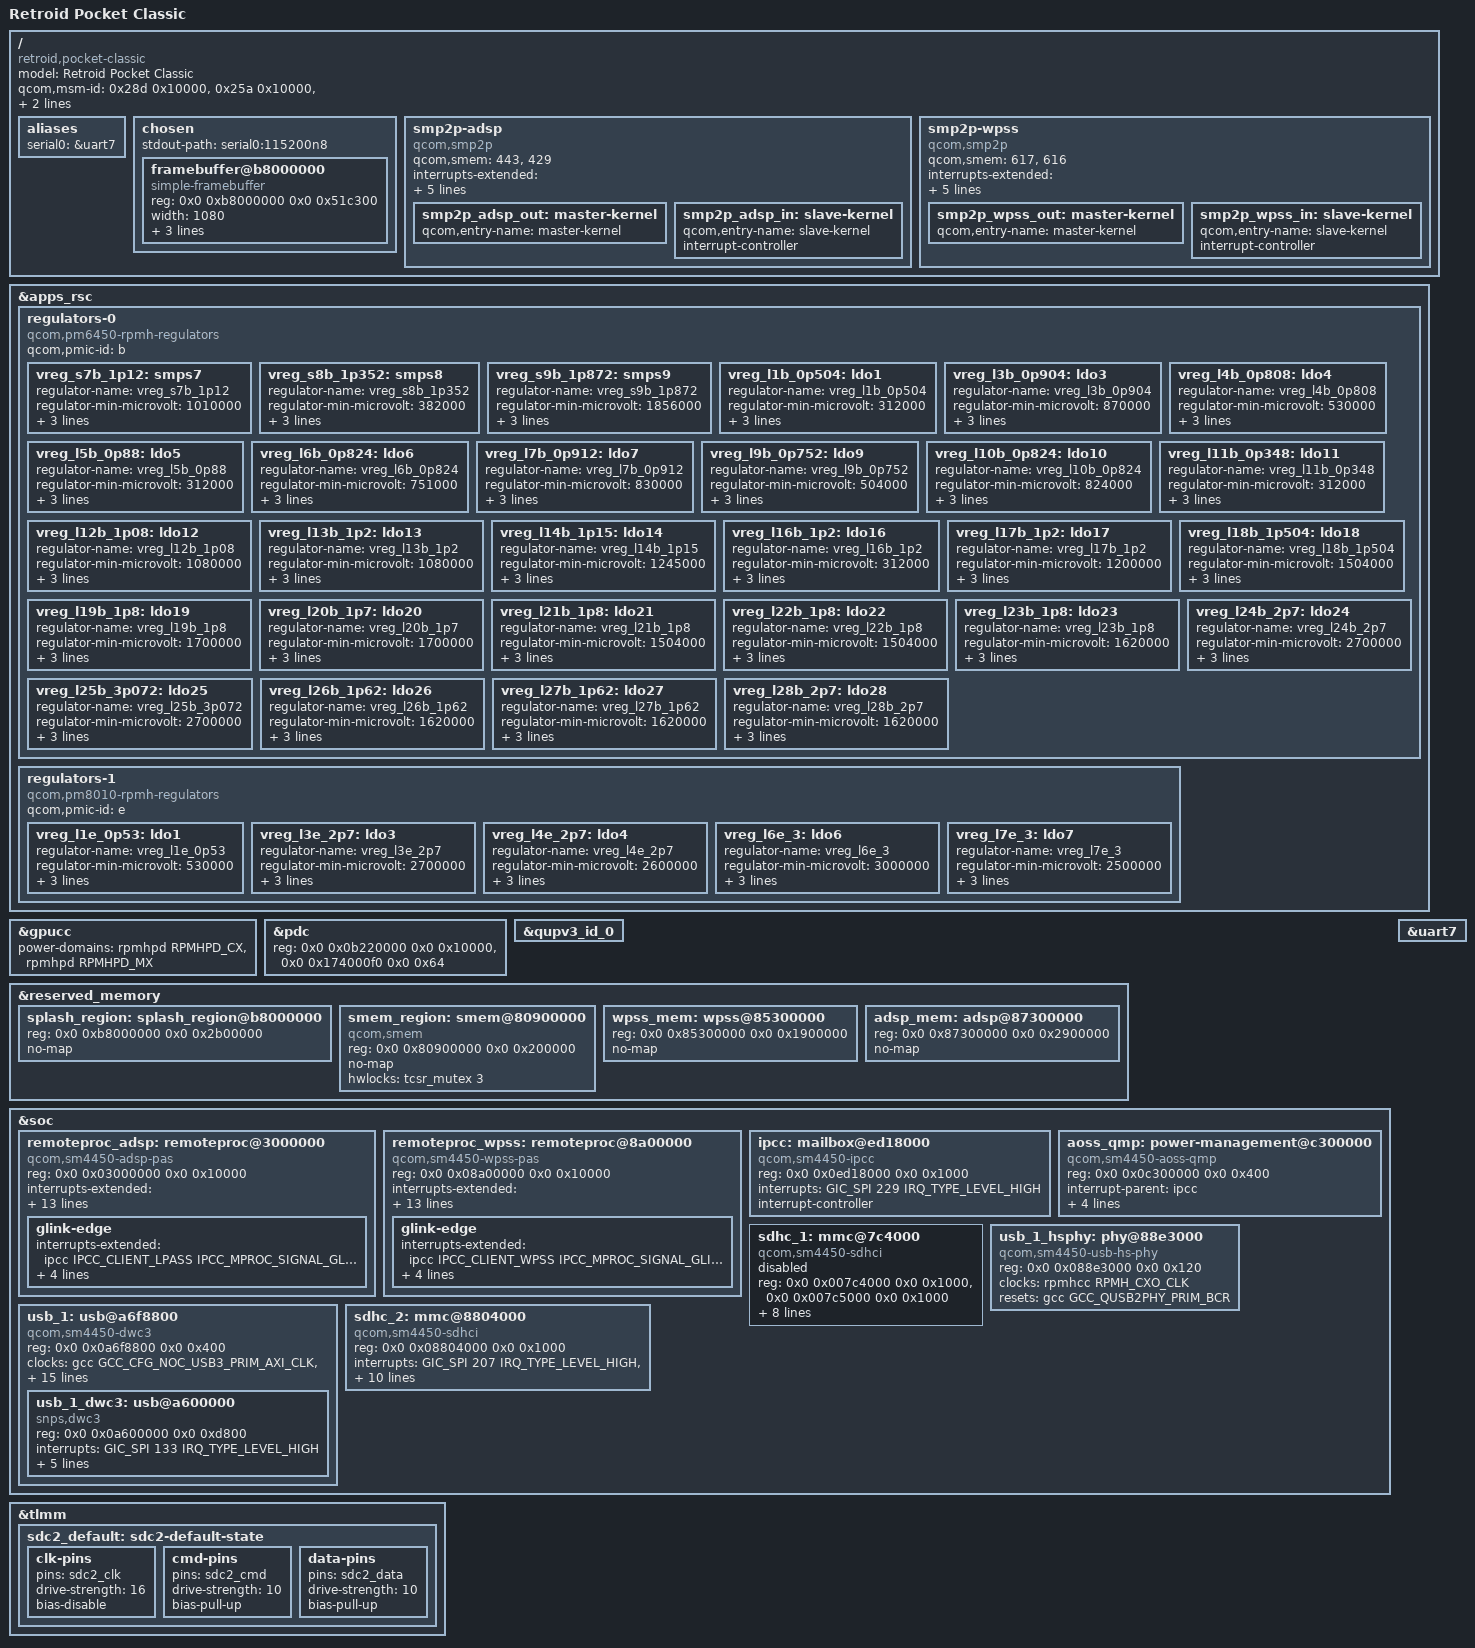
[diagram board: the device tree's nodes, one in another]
// SPDX-License-Identifier: BSD-3-Clause
/*
 * Retroid Pocket Classic (SM4450 "parrot")
 *
 * Hardware data from the live Android DT dump (2026-08-22).
 */

/dts-v1/;

#include <dt-bindings/gpio/gpio.h>
#include <dt-bindings/mailbox/qcom-ipcc.h>
#include <dt-bindings/regulator/qcom,rpmh-regulator.h>
#include "sm4450.dtsi"
/ {
	model = "Retroid Pocket Classic";
	compatible = "retroid,pocket-classic", "qcom,sm4450";
	qcom,msm-id = <0x28d 0x10000>, <0x25a 0x10000>, <0x28e 0x10000>;
	qcom,board-id = <0x1000b 0>;

	aliases {
		serial0 = &uart7;
	};

	chosen {
		#address-cells = <2>;
		#size-cells = <2>;
		ranges;
		stdout-path = "serial0:115200n8";

		framebuffer@b8000000 {
			compatible = "simple-framebuffer";
			reg = <0x0 0xb8000000 0x0 0x51c300>;
			width = <1080>;
			height = <1240>;
			stride = <4320>;
			format = "x8r8g8b8";
			status = "okay";
		};
	};

	smp2p-adsp {
		compatible = "qcom,smp2p";
		qcom,smem = <443>, <429>;
		interrupts-extended = <&ipcc IPCC_CLIENT_LPASS
					     IPCC_MPROC_SIGNAL_SMP2P
					     IRQ_TYPE_EDGE_RISING>;
		mboxes = <&ipcc IPCC_CLIENT_LPASS IPCC_MPROC_SIGNAL_SMP2P>;
		qcom,local-pid = <0>;
		qcom,remote-pid = <2>;

		smp2p_adsp_out: master-kernel {
			qcom,entry-name = "master-kernel";
			#qcom,smem-state-cells = <1>;
		};

		smp2p_adsp_in: slave-kernel {
			qcom,entry-name = "slave-kernel";
			interrupt-controller;
			#interrupt-cells = <2>;
		};
	};

	smp2p-wpss {
		compatible = "qcom,smp2p";
		qcom,smem = <617>, <616>;
		interrupts-extended = <&ipcc IPCC_CLIENT_WPSS
					     IPCC_MPROC_SIGNAL_SMP2P
					     IRQ_TYPE_EDGE_RISING>;
		mboxes = <&ipcc IPCC_CLIENT_WPSS IPCC_MPROC_SIGNAL_SMP2P>;
		qcom,local-pid = <0>;
		qcom,remote-pid = <13>;

		smp2p_wpss_out: master-kernel {
			qcom,entry-name = "master-kernel";
			#qcom,smem-state-cells = <1>;
		};

		smp2p_wpss_in: slave-kernel {
			qcom,entry-name = "slave-kernel";
			interrupt-controller;
			#interrupt-cells = <2>;
		};
	};
};

&apps_rsc {
	/* Voltage constraints extracted from the live parrot (RP Classic) DT */
	regulators-0 {
		compatible = "qcom,pm6450-rpmh-regulators";
		qcom,pmic-id = "b";

		vreg_s7b_1p12: smps7 {
			regulator-name = "vreg_s7b_1p12";
			regulator-min-microvolt = <1010000>;
			regulator-max-microvolt = <1170000>;
			regulator-initial-mode = <RPMH_REGULATOR_MODE_HPM>;
		};
		vreg_s8b_1p352: smps8 {
			regulator-name = "vreg_s8b_1p352";
			regulator-min-microvolt = <382000>;
			regulator-max-microvolt = <1744000>;
			regulator-initial-mode = <RPMH_REGULATOR_MODE_HPM>;
		};
		vreg_s9b_1p872: smps9 {
			regulator-name = "vreg_s9b_1p872";
			regulator-min-microvolt = <1856000>;
			regulator-max-microvolt = <2040000>;
			regulator-initial-mode = <RPMH_REGULATOR_MODE_HPM>;
		};
		vreg_l1b_0p504: ldo1 {
			regulator-name = "vreg_l1b_0p504";
			regulator-min-microvolt = <312000>;
			regulator-max-microvolt = <650000>;
			regulator-initial-mode = <RPMH_REGULATOR_MODE_HPM>;
		};
		vreg_l3b_0p904: ldo3 {
			regulator-name = "vreg_l3b_0p904";
			regulator-min-microvolt = <870000>;
			regulator-max-microvolt = <970000>;
			regulator-initial-mode = <RPMH_REGULATOR_MODE_HPM>;
		};
		vreg_l4b_0p808: ldo4 {
			regulator-name = "vreg_l4b_0p808";
			regulator-min-microvolt = <530000>;
			regulator-max-microvolt = <860000>;
			regulator-initial-mode = <RPMH_REGULATOR_MODE_HPM>;
		};
		vreg_l5b_0p88: ldo5 {
			regulator-name = "vreg_l5b_0p88";
			regulator-min-microvolt = <312000>;
			regulator-max-microvolt = <1052000>;
			regulator-initial-mode = <RPMH_REGULATOR_MODE_HPM>;
		};
		vreg_l6b_0p824: ldo6 {
			regulator-name = "vreg_l6b_0p824";
			regulator-min-microvolt = <751000>;
			regulator-max-microvolt = <824000>;
			regulator-initial-mode = <RPMH_REGULATOR_MODE_HPM>;
		};
		vreg_l7b_0p912: ldo7 {
			regulator-name = "vreg_l7b_0p912";
			regulator-min-microvolt = <830000>;
			regulator-max-microvolt = <920000>;
			regulator-initial-mode = <RPMH_REGULATOR_MODE_HPM>;
		};
		vreg_l9b_0p752: ldo9 {
			regulator-name = "vreg_l9b_0p752";
			regulator-min-microvolt = <504000>;
			regulator-max-microvolt = <824000>;
			regulator-initial-mode = <RPMH_REGULATOR_MODE_HPM>;
		};
		vreg_l10b_0p824: ldo10 {
			regulator-name = "vreg_l10b_0p824";
			regulator-min-microvolt = <824000>;
			regulator-max-microvolt = <901000>;
			regulator-initial-mode = <RPMH_REGULATOR_MODE_HPM>;
		};
		vreg_l11b_0p348: ldo11 {
			regulator-name = "vreg_l11b_0p348";
			regulator-min-microvolt = <312000>;
			regulator-max-microvolt = <752000>;
			regulator-initial-mode = <RPMH_REGULATOR_MODE_HPM>;
		};
		vreg_l12b_1p08: ldo12 {
			regulator-name = "vreg_l12b_1p08";
			regulator-min-microvolt = <1080000>;
			regulator-max-microvolt = <1304000>;
			regulator-initial-mode = <RPMH_REGULATOR_MODE_HPM>;
		};
		vreg_l13b_1p2: ldo13 {
			regulator-name = "vreg_l13b_1p2";
			regulator-min-microvolt = <1080000>;
			regulator-max-microvolt = <1304000>;
			regulator-initial-mode = <RPMH_REGULATOR_MODE_HPM>;
		};
		vreg_l14b_1p15: ldo14 {
			regulator-name = "vreg_l14b_1p15";
			regulator-min-microvolt = <1245000>;
			regulator-max-microvolt = <1304000>;
			regulator-initial-mode = <RPMH_REGULATOR_MODE_HPM>;
		};
		vreg_l16b_1p2: ldo16 {
			regulator-name = "vreg_l16b_1p2";
			regulator-min-microvolt = <312000>;
			regulator-max-microvolt = <1260000>;
			regulator-initial-mode = <RPMH_REGULATOR_MODE_HPM>;
		};
		vreg_l17b_1p2: ldo17 {
			regulator-name = "vreg_l17b_1p2";
			regulator-min-microvolt = <1200000>;
			regulator-max-microvolt = <1200000>;
			regulator-initial-mode = <RPMH_REGULATOR_MODE_HPM>;
		};
		vreg_l18b_1p504: ldo18 {
			regulator-name = "vreg_l18b_1p504";
			regulator-min-microvolt = <1504000>;
			regulator-max-microvolt = <2000000>;
			regulator-initial-mode = <RPMH_REGULATOR_MODE_HPM>;
		};
		vreg_l19b_1p8: ldo19 {
			regulator-name = "vreg_l19b_1p8";
			regulator-min-microvolt = <1700000>;
			regulator-max-microvolt = <1950000>;
			regulator-initial-mode = <RPMH_REGULATOR_MODE_HPM>;
		};
		vreg_l20b_1p7: ldo20 {
			regulator-name = "vreg_l20b_1p7";
			regulator-min-microvolt = <1700000>;
			regulator-max-microvolt = <1900000>;
			regulator-initial-mode = <RPMH_REGULATOR_MODE_HPM>;
		};
		vreg_l21b_1p8: ldo21 {
			regulator-name = "vreg_l21b_1p8";
			regulator-min-microvolt = <1504000>;
			regulator-max-microvolt = <2000000>;
			regulator-initial-mode = <RPMH_REGULATOR_MODE_HPM>;
		};
		vreg_l22b_1p8: ldo22 {
			regulator-name = "vreg_l22b_1p8";
			regulator-min-microvolt = <1504000>;
			regulator-max-microvolt = <2000000>;
			regulator-initial-mode = <RPMH_REGULATOR_MODE_HPM>;
		};
		vreg_l23b_1p8: ldo23 {
			regulator-name = "vreg_l23b_1p8";
			regulator-min-microvolt = <1620000>;
			regulator-max-microvolt = <1980000>;
			regulator-initial-mode = <RPMH_REGULATOR_MODE_HPM>;
		};
		vreg_l24b_2p7: ldo24 {
			regulator-name = "vreg_l24b_2p7";
			regulator-min-microvolt = <2700000>;
			regulator-max-microvolt = <3544000>;
			regulator-initial-mode = <RPMH_REGULATOR_MODE_HPM>;
		};
		vreg_l25b_3p072: ldo25 {
			regulator-name = "vreg_l25b_3p072";
			regulator-min-microvolt = <2700000>;
			regulator-max-microvolt = <3544000>;
			regulator-initial-mode = <RPMH_REGULATOR_MODE_HPM>;
		};
		vreg_l26b_1p62: ldo26 {
			regulator-name = "vreg_l26b_1p62";
			regulator-min-microvolt = <1620000>;
			regulator-max-microvolt = <3300000>;
			regulator-initial-mode = <RPMH_REGULATOR_MODE_HPM>;
		};
		vreg_l27b_1p62: ldo27 {
			regulator-name = "vreg_l27b_1p62";
			regulator-min-microvolt = <1620000>;
			regulator-max-microvolt = <3300000>;
			regulator-initial-mode = <RPMH_REGULATOR_MODE_HPM>;
		};
		vreg_l28b_2p7: ldo28 {
			regulator-name = "vreg_l28b_2p7";
			regulator-min-microvolt = <1620000>;
			regulator-max-microvolt = <3300000>;
			regulator-initial-mode = <RPMH_REGULATOR_MODE_HPM>;
		};
	};

	regulators-1 {
		compatible = "qcom,pm8010-rpmh-regulators";
		qcom,pmic-id = "e";

		vreg_l1e_0p53: ldo1 {
			regulator-name = "vreg_l1e_0p53";
			regulator-min-microvolt = <530000>;
			regulator-max-microvolt = <530000>;
			regulator-initial-mode = <RPMH_REGULATOR_MODE_HPM>;
		};
		vreg_l3e_2p7: ldo3 {
			regulator-name = "vreg_l3e_2p7";
			regulator-min-microvolt = <2700000>;
			regulator-max-microvolt = <3300000>;
			regulator-initial-mode = <RPMH_REGULATOR_MODE_HPM>;
		};
		vreg_l4e_2p7: ldo4 {
			regulator-name = "vreg_l4e_2p7";
			regulator-min-microvolt = <2600000>;
			regulator-max-microvolt = <3312000>;
			regulator-initial-mode = <RPMH_REGULATOR_MODE_HPM>;
		};
		vreg_l6e_3: ldo6 {
			regulator-name = "vreg_l6e_3";
			regulator-min-microvolt = <3000000>;
			regulator-max-microvolt = <3312000>;
			regulator-initial-mode = <RPMH_REGULATOR_MODE_HPM>;
		};
		vreg_l7e_3: ldo7 {
			regulator-name = "vreg_l7e_3";
			regulator-min-microvolt = <2500000>;
			regulator-max-microvolt = <3544000>;
			regulator-initial-mode = <RPMH_REGULATOR_MODE_HPM>;
		};
	};
};

/* Pending upstream Konrad GPU_CC patch */
&gpucc {
	power-domains = <&rpmhpd RPMHPD_CX>,
			<&rpmhpd RPMHPD_MX>;
};

&pdc {
	reg = <0x0 0x0b220000 0x0 0x10000>, <0x0 0x174000f0 0x0 0x64>;
};

&qupv3_id_0 {
	status = "okay";
};

&reserved_memory {
	splash_region: splash_region@b8000000 {
		reg = <0x0 0xb8000000 0x0 0x2b00000>;
		no-map;
	};

	smem_region: smem@80900000 {
		compatible = "qcom,smem";
		reg = <0x0 0x80900000 0x0 0x200000>;
		no-map;
		hwlocks = <&tcsr_mutex 3>;
	};

	wpss_mem: wpss@85300000 {
		reg = <0x0 0x85300000 0x0 0x1900000>;
		no-map;
	};

	adsp_mem: adsp@87300000 {
		reg = <0x0 0x87300000 0x0 0x2900000>;
		no-map;
	};
};

&soc {
	remoteproc_adsp: remoteproc@3000000 {
		compatible = "qcom,sm4450-adsp-pas";
		reg = <0x0 0x03000000 0x0 0x10000>;

		interrupts-extended = <&pdc 6 IRQ_TYPE_EDGE_RISING>,
				      <&smp2p_adsp_in 0 IRQ_TYPE_EDGE_RISING>,
				      <&smp2p_adsp_in 1 IRQ_TYPE_EDGE_RISING>,
				      <&smp2p_adsp_in 2 IRQ_TYPE_EDGE_RISING>,
				      <&smp2p_adsp_in 3 IRQ_TYPE_EDGE_RISING>;
		interrupt-names = "wdog", "fatal", "ready",
				  "handover", "stop-ack";

		clocks = <&rpmhcc RPMH_CXO_CLK>;
		clock-names = "xo";

		power-domains = <&rpmhpd RPMHPD_LCX>,
				<&rpmhpd RPMHPD_LMX>;
		power-domain-names = "lcx", "lmx";

		memory-region = <&adsp_mem>;

		qcom,qmp = <&aoss_qmp>;
		qcom,smem-states = <&smp2p_adsp_out 0>;
		qcom,smem-state-names = "stop";

		firmware-name = "qcom/sm4450/adsp.mbn";

		/* TODO: audio service bring up */
		glink-edge {
			interrupts-extended = <&ipcc IPCC_CLIENT_LPASS
						     IPCC_MPROC_SIGNAL_GLINK_QMP
						     IRQ_TYPE_EDGE_RISING>;
			mboxes = <&ipcc IPCC_CLIENT_LPASS
					IPCC_MPROC_SIGNAL_GLINK_QMP>;
			label = "lpass";
			qcom,remote-pid = <2>;
		};
	};

	remoteproc_wpss: remoteproc@8a00000 {
		compatible = "qcom,sm4450-wpss-pas";
		reg = <0x0 0x08a00000 0x0 0x10000>;

		interrupts-extended = <&intc GIC_SPI 587 IRQ_TYPE_EDGE_RISING>,
				      <&smp2p_wpss_in 0 IRQ_TYPE_EDGE_RISING>,
				      <&smp2p_wpss_in 1 IRQ_TYPE_EDGE_RISING>,
				      <&smp2p_wpss_in 2 IRQ_TYPE_EDGE_RISING>,
				      <&smp2p_wpss_in 3 IRQ_TYPE_EDGE_RISING>;
		interrupt-names = "wdog", "fatal", "ready",
				  "handover", "stop-ack";

		clocks = <&rpmhcc RPMH_CXO_CLK>;
		clock-names = "xo";

		power-domains = <&rpmhpd RPMHPD_CX>,
				<&rpmhpd RPMHPD_MX>;
		power-domain-names = "cx", "mx";

		memory-region = <&wpss_mem>;

		qcom,qmp = <&aoss_qmp>;
		qcom,smem-states = <&smp2p_wpss_out 0>;
		qcom,smem-state-names = "stop";

		firmware-name = "qcom/sm4450/wpss.mbn";

		/* TODO: ath11k WCN6750 (?) node */
		glink-edge {
			interrupts-extended = <&ipcc IPCC_CLIENT_WPSS
						     IPCC_MPROC_SIGNAL_GLINK_QMP
						     IRQ_TYPE_EDGE_RISING>;
			mboxes = <&ipcc IPCC_CLIENT_WPSS
					IPCC_MPROC_SIGNAL_GLINK_QMP>;
			label = "wpss";
			qcom,remote-pid = <13>;
		};
	};

	ipcc: mailbox@ed18000 {
		compatible = "qcom,sm4450-ipcc", "qcom,ipcc";
		reg = <0x0 0x0ed18000 0x0 0x1000>;
		interrupts = <GIC_SPI 229 IRQ_TYPE_LEVEL_HIGH>;
		interrupt-controller;
		#interrupt-cells = <3>;
		#mbox-cells = <2>;
	};

	aoss_qmp: power-management@c300000 {
		compatible = "qcom,sm4450-aoss-qmp", "qcom,aoss-qmp";
		reg = <0x0 0x0c300000 0x0 0x400>;
		interrupt-parent = <&ipcc>;
		interrupts-extended = <&ipcc IPCC_CLIENT_AOP
					     IPCC_MPROC_SIGNAL_GLINK_QMP
					     IRQ_TYPE_EDGE_RISING>;
		mboxes = <&ipcc IPCC_CLIENT_AOP IPCC_MPROC_SIGNAL_GLINK_QMP>;
		#clock-cells = <0>;
	};

	sdhc_1: mmc@7c4000 {
		compatible = "qcom,sm4450-sdhci", "qcom,sdhci-msm-v5";
		reg = <0x0 0x007c4000 0x0 0x1000>,
		      <0x0 0x007c5000 0x0 0x1000>;
		reg-names = "hc", "cqhci";
		interrupts = <GIC_SPI 135 IRQ_TYPE_LEVEL_HIGH>,
			     <GIC_SPI 137 IRQ_TYPE_LEVEL_HIGH>;
		interrupt-names = "hc_irq", "pwr_irq";
		clocks = <&gcc GCC_SDCC1_AHB_CLK>,
			 <&gcc GCC_SDCC1_APPS_CLK>,
			 <&rpmhcc RPMH_CXO_CLK>;
		clock-names = "iface", "core", "xo";
		power-domains = <&rpmhpd RPMHPD_CX>;
		bus-width = <8>;
		supports-cqe;
		non-removable;
		status = "disabled";
	};

	usb_1_hsphy: phy@88e3000 {
		compatible = "qcom,sm4450-usb-hs-phy",
			     "qcom,usb-snps-hs-7nm-phy";
		reg = <0x0 0x088e3000 0x0 0x120>;
		#phy-cells = <0>;
		clocks = <&rpmhcc RPMH_CXO_CLK>;
		clock-names = "ref";
		resets = <&gcc GCC_QUSB2PHY_PRIM_BCR>;
	};

	usb_1: usb@a6f8800 {
		compatible = "qcom,sm4450-dwc3", "qcom,dwc3";
		reg = <0x0 0x0a6f8800 0x0 0x400>;
		#address-cells = <2>;
		#size-cells = <2>;
		ranges;

		clocks = <&gcc GCC_CFG_NOC_USB3_PRIM_AXI_CLK>,
			 <&gcc GCC_USB30_PRIM_MASTER_CLK>,
			 <&gcc GCC_AGGRE_USB3_PRIM_AXI_CLK>,
			 <&gcc GCC_USB30_PRIM_SLEEP_CLK>,
			 <&gcc GCC_USB30_PRIM_MOCK_UTMI_CLK>;
		clock-names = "cfg_noc",
			      "core",
			      "iface",
			      "sleep",
			      "mock_utmi";

		assigned-clocks = <&gcc GCC_USB30_PRIM_MOCK_UTMI_CLK>,
				  <&gcc GCC_USB30_PRIM_MASTER_CLK>;
		assigned-clock-rates = <19200000>, <133333333>;

		interrupts-extended = <&intc GIC_SPI 130 IRQ_TYPE_LEVEL_HIGH>,
				      <&pdc 14 IRQ_TYPE_EDGE_BOTH>,
				      <&pdc 15 IRQ_TYPE_EDGE_BOTH>,
				      <&pdc 17 IRQ_TYPE_LEVEL_HIGH>;
		interrupt-names = "pwr_event",
				  "dp_hs_phy_irq",
				  "dm_hs_phy_irq",
				  "ss_phy_irq";

		power-domains = <&gcc GCC_USB30_PRIM_GDSC>;

		resets = <&gcc GCC_USB30_PRIM_BCR>;

		usb_1_dwc3: usb@a600000 {
			compatible = "snps,dwc3";
			reg = <0x0 0x0a600000 0x0 0xd800>;
			interrupts = <GIC_SPI 133 IRQ_TYPE_LEVEL_HIGH>;
			snps,dis_u2_susphy_quirk;
			snps,dis_enblslpm_quirk;
			phys = <&usb_1_hsphy>;
			phy-names = "usb2-phy";
			/* TODO: HS only for now */
			maximum-speed = "high-speed";
			/* TODO: role switch via tcpm once PD controller is wired */
			dr_mode = "peripheral";
		};
	};

	sdhc_2: mmc@8804000 {
		compatible = "qcom,sm4450-sdhci", "qcom,sdhci-msm-v5";
		reg = <0x0 0x08804000 0x0 0x1000>;
		reg-names = "hc";
		interrupts = <GIC_SPI 207 IRQ_TYPE_LEVEL_HIGH>,
			     <GIC_SPI 223 IRQ_TYPE_LEVEL_HIGH>;
		interrupt-names = "hc_irq", "pwr_irq";
		clocks = <&gcc GCC_SDCC2_AHB_CLK>,
			 <&gcc GCC_SDCC2_APPS_CLK>,
			 <&rpmhcc RPMH_CXO_CLK>;
		clock-names = "iface", "core", "xo";
		power-domains = <&rpmhpd RPMHPD_CX>;
		pinctrl-0 = <&sdc2_default>;
		pinctrl-names = "default";
		vmmc-supply = <&vreg_l24b_2p7>;
		vqmmc-supply = <&vreg_l28b_2p7>;
		bus-width = <4>;
		/* card detect on TLMM 101, active low (from live parrot DT) */
		cd-gpios = <&tlmm 101 GPIO_ACTIVE_LOW>;
		no-sdio;
		status = "okay";
	};
};

&tlmm {
	sdc2_default: sdc2-default-state {
		clk-pins {
			pins = "sdc2_clk";
			drive-strength = <16>;
			bias-disable;
		};

		cmd-pins {
			pins = "sdc2_cmd";
			drive-strength = <10>;
			bias-pull-up;
		};

		data-pins {
			pins = "sdc2_data";
			drive-strength = <10>;
			bias-pull-up;
		};
	};
};

/* Debug console, geni SE @ 0xa88000 (verified against live DT) */
&uart7 {
	status = "okay";
};
